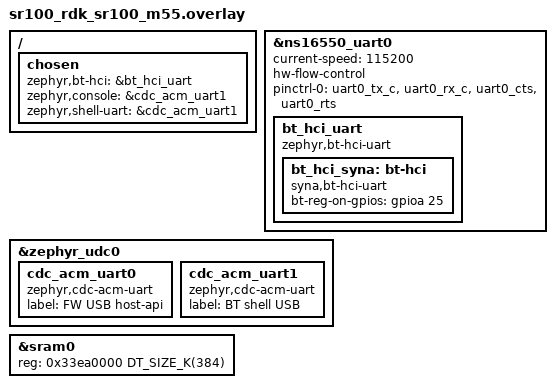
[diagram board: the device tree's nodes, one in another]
/*
 * Dual CDC ACM for merged BT shell + FW host-api sample.
 * cdc_acm_uart0: host-api flashing channel
 * cdc_acm_uart1: Zephyr shell console
 */

/ {
	chosen {
		zephyr,bt-hci = &bt_hci_uart;
		zephyr,console = &cdc_acm_uart1;
		zephyr,shell-uart = &cdc_acm_uart1;
	};
};

&ns16550_uart0 {
	status = "okay";
	current-speed = <115200>;
	hw-flow-control;
	pinctrl-0 = <&uart0_tx_c &uart0_rx_c &uart0_cts &uart0_rts>;
	pinctrl-names = "default";

	bt_hci_uart: bt_hci_uart {
		compatible = "zephyr,bt-hci-uart";
		status = "okay";

		bt_hci_syna: bt-hci {
			compatible = "syna,bt-hci-uart";
			status = "okay";
			bt-reg-on-gpios = <&gpioa 25 GPIO_ACTIVE_HIGH>;
		};
	};
};

&zephyr_udc0 {
	cdc_acm_uart0: cdc_acm_uart0 {
		compatible = "zephyr,cdc-acm-uart";
		label = "FW USB host-api";
	};

	cdc_acm_uart1: cdc_acm_uart1 {
		compatible = "zephyr,cdc-acm-uart";
		label = "BT shell USB";
	};
};

&sram0 {
	reg = <0x33ea0000 DT_SIZE_K(384)>;
	ranges = <0x0 0x33ea0000 DT_SIZE_K(384)>;
};
